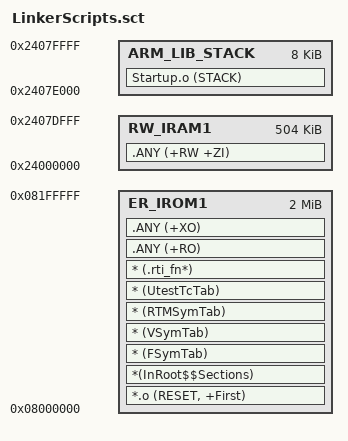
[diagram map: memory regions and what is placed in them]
; *************************************************************
; *** Scatter-Loading Description File generated by uVision ***
; *************************************************************

LR_IROM1 0x08000000 0x00200000  {    ; STM32H743 internal Flash, 2 MB
  ER_IROM1 0x08000000 0x00200000  {  ; load address = execution address
   *.o (RESET, +First)
   *(InRoot$$Sections)

   ; RT-Thread registration tables must stay contiguous and must be placed
   ; before .ANY. The linker generates SectionName$$Base/Limit symbols for
   ; FinSH, module and utest code to locate these tables at run time.
   * (FSymTab)
   * (VSymTab)
   * (RTMSymTab)
   * (UtestTcTab)
   * (.rti_fn*)

   .ANY (+RO)
   .ANY (+XO)
  }
  ; RT-Thread keeps ordinary RW/ZI data and its heap in AXI SRAM. DTCM is
  ; intentionally not the default because general DMA masters cannot access it.
  RW_IRAM1 0x24000000 0x0007E000  {  ; AXI SRAM below the main stack
   .ANY (+RW +ZI)
  }
  ARM_LIB_STACK 0x2407E000 0x00002000  {  ; Reserve 8 KB at AXI SRAM top
   Startup.o (STACK)
  }
}
